# RL6955_IP_SVD register map
Vendor: Realtek
Registers are 32-bit, read-write, reset 0x0 unless marked. A register's access mark holds for its fields unless they carry their own. Offsets are from the block's base; [hi:lo] are bit positions; {n}, {i} and the like mark numbered series; <NAME> marks a mode.

## WMAC_PAGE7
Base 0x40000000
0x700 REG_MACID1
  [31:0] WMAC_MACID1_L — MAC Identification Number Register for port 1. relay mode as soft ap macid
0x704 REG_MACID1_1
  [15:0] WMAC_MACID1_H — MAC Identification Number Register for port 1. relay mode as soft ap macid
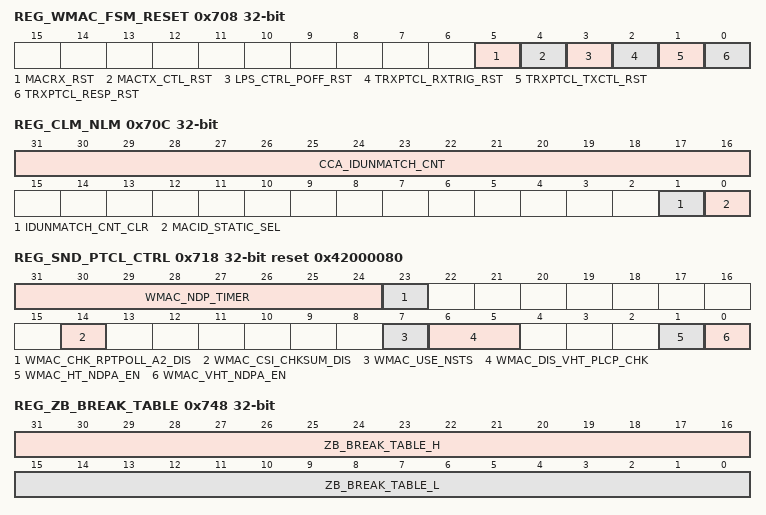
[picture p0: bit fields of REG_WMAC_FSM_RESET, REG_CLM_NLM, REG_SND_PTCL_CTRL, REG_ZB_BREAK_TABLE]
0x708 REG_WMAC_FSM_RESET wo
  [5] MACRX_RST — write 1 to RESET FSM of macrx
  [4] MACTX_CTL_RST — write 1 to RESET FSM of mactx_ctl
  [3] LPS_CTRL_POFF_RST — write 1 to RESET FSM of wmac_tlps_ctrl_poff
  [2] TRXPTCL_RXTRIG_RST — write 1 to RESET FSM of wmac_trxptcl_rxtig
  [1] TRXPTCL_TXCTL_RST — write 1 to RESET FSM of wmac_trxptcl_txctl
  [0] TRXPTCL_RESP_RST — write 1 to RESET FSM of wmac_trxptcl_resp
0x70C REG_CLM_NLM access per field
  [31:16] CCA_IDUNMATCH_CNT ro — not my packet counter
  [1] IDUNMATCH_CNT_CLR wo — write 1 to reset cca_idunmatch_cnt
  [0] MACID_STATIC_SEL rw — 1:statistic a1 match packet;0:statistic a1 match packet,my bss bc and mc packet
0x710 REG_MACID2
  [31:0] WMAC_MACID2_L — MAC Identification Number Register for port 2. relay mode, enable r_P2_WTNAP, as relay ap addr
0x714 REG_MACID2_1
  [15:0] WMAC_MACID2_H — MAC Identification Number Register for port 2 relay mode, enable r_P2_WTNAP, as relay ap addr
0x718 REG_SND_PTCL_CTRL reset 0x42000080
  [31:24] WMAC_NDP_TIMER — A timeout value for MAC to leave NDP_Rx_standby_state and go back to normal Rx mode. (unit: 2us)
  [23] WMAC_CHK_RPTPOLL_A2_DIS — 1: For any A1-matched BF Rpt Poll, send back VHT-CB 0: If A1-matched BF Rpt Poll's A2 fails to match the previous receiving NDPA's A2, do not send VHT-CB
  [14] WMAC_CSI_CHKSUM_DIS — 1:Disable check 16bit checksum value of csi report from BB 0:Enable check 16bit checksum value of csi report from BB
  [7] WMAC_USE_NSTS — 1: use Nsts as Nr, 0: use register value as Nr
  [6:5] WMAC_DIS_VHT_PLCP_CHK — [6]:1: disable check vhtsigb crc [5]:1: disable check vhtsiga crc
  [1] WMAC_HT_NDPA_EN — Set to 1, MAC would inform BB of preparing to receive NDP if the received NDP Announcement MPDU is valid.
  [0] WMAC_VHT_NDPA_EN — Set to 1, MAC would inform BB of preparing to receive NDP if the received NDPA is valid.
0x71C REG_BEAMFORM_STATUS
  [30] WMAC_CHECK_SOUNDING_SEQ — Set to 1,MAC would check sounding sequence number of received CSI report and transmitted NDPA
0x720 REG_ZB_STATISTIC_0 wo
  [0] STATIS_ZB_RSTB
0x724 REG_ZB_STATISTIC_1 ro
  [31:0] STATIS_ZG_L — for statistic
0x728 REG_ZB_STATISTIC_2 ro
  [31:0] STATIS_ZG_H — for statistic
0x740 REG_ZB_COEX_TABLE_1
  [31:0] ZB_COEX_TABLE_1 — coexistence table between WLAN and Zigbee, selected by BIT_COEX_TABLE_SEL = 0
0x744 REG_ZB_COEX_TABLE_2
  [31:0] ZB_COEX_TABLE_2 — coexistence table between WLAN and Zigbee, selected by BIT_COEX_TABLE_SEL = 1
0x748 REG_ZB_BREAK_TABLE
  [31:16] ZB_BREAK_TABLE_H — Table used to break ZB activity, when new WLAN request is coming and ZB is on transmitting or receiving
  [15:0] ZB_BREAK_TABLE_L — Table used to break WLAN activity, when new ZB request is coming and WLAN is on transmitting or receiving
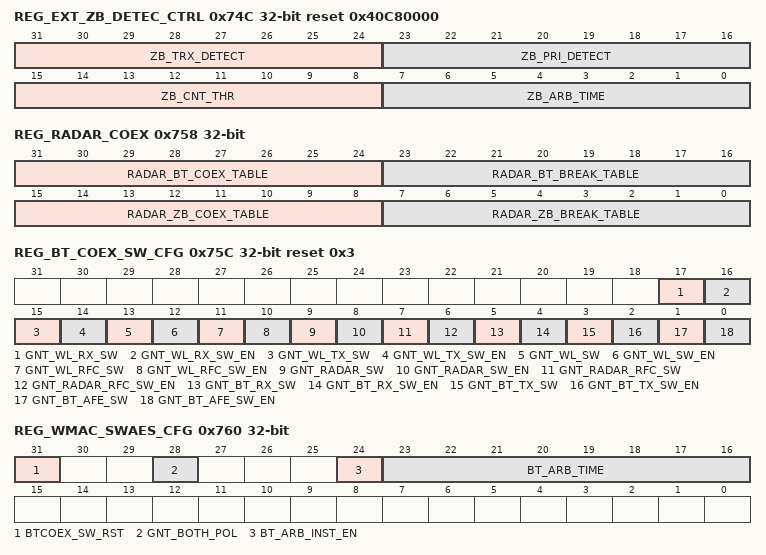
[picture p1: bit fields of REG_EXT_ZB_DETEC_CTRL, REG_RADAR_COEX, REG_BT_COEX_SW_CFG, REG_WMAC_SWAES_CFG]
0x74C REG_EXT_ZB_DETEC_CTRL reset 0x40C80000
  [31:24] ZB_TRX_DETECT — Valid if BIT_ZIGBEE_MODE = 1 & BIT_EXT_ZIGBEE_MODE = 0 (external mode, directional PRIORITY) After ZB_PRI_DETECT_TIME duration, if ZB_PRIORITY is low or goes low during ZB_TRX_INIT_DETECT_TIME, Zigbee will receive packets; otherwise, if ZG_PRIORITY is high or goes high, ZB will TX data. Unit 1us.
  [23:16] ZB_PRI_DETECT — Valid if BIT_ZIGBEE_MODE = 1 & BIT_EXT_ZIGBEE_MODE = 0 (external mode, directional PRIORITY) After ZB_REQUEST asserting, if ZG_PRIORITY is asserted within this ZB_PRI_DETECT_TIME duration, ZG will initiate high priority activities; otherwise, if ZB_PRIORITY is not asserted within this duration, it would be low priority activities. Units 1us. (0-255us)
  [15:8] ZB_CNT_THR — ZB count threshold, unit: us
  [7:0] ZB_ARB_TIME — 8 bit timer register : Arbitration window of ZB trx request (unit: us)
0x758 REG_RADAR_COEX
  [31:24] RADAR_BT_COEX_TABLE — COEX table of radar & BT, radar force wl_tx = 1, wl_pri = 1
  [23:16] RADAR_BT_BREAK_TABLE — BREAK table of radar & BT, radar force wl_tx = 1, wl_pri = 1
  [15:8] RADAR_ZB_COEX_TABLE — COEX table of radar & ZB, radar force wl_tx = 1, wl_pri = 1
  [7:0] RADAR_ZB_BREAK_TABLE — BREAK table of radar & ZB, radar force wl_tx = 1, wl_pri = 1
0x75C REG_BT_COEX_SW_CFG reset 0x3
  [17] GNT_WL_RX_SW — SW control GNT_WL_RX
  [16] GNT_WL_RX_SW_EN — SW control GNT_WL_RX enable
  [15] GNT_WL_TX_SW — SW control GNT_WL_TX
  [14] GNT_WL_TX_SW_EN — SW control GNT_WL_TX enable
  [13] GNT_WL_SW — SW control GNT_WL
  [12] GNT_WL_SW_EN — SW control GNT_WL enable
  [11] GNT_WL_RFC_SW — SW control GNT_WL_RFC
  [10] GNT_WL_RFC_SW_EN — SW control GNT_WL_RFC enable
  [9] GNT_RADAR_SW — SW control GNT_RADAR
  [8] GNT_RADAR_SW_EN — SW control GNT_RADAR enable
  [7] GNT_RADAR_RFC_SW — SW control GNT_RADAR_RFC
  [6] GNT_RADAR_RFC_SW_EN — SW control GNT_RADAR_RFC enable
  [5] GNT_BT_RX_SW — SW control GNT_BT_RX
  [4] GNT_BT_RX_SW_EN — SW control GNT_BT_RX enable
  [3] GNT_BT_TX_SW — SW control GNT_BT_TX
  [2] GNT_BT_TX_SW_EN — SW control GNT_BT_TX enable
  [1] GNT_BT_AFE_SW — SW control BT AFE
  [0] GNT_BT_AFE_SW_EN — SW control BT AFE enable
0x760 REG_WMAC_SWAES_CFG
  [31] BTCOEX_SW_RST
  [28] GNT_BOTH_POL — grant both choose GNT_BT polarity: 0 : deassert GNT_BT signal as PTA grant both WiFI and BT. 1 : assert GNT_BT signal as PTA grant both WiFi and BT.
  [24] BT_ARB_INST_EN — 1: enable GNT_BT_BYPASS_PRIORITY 0 : disable
  [23:16] BT_ARB_TIME — 8 bit timer register : Arbitration window of bt trx request ( in the unit of us)
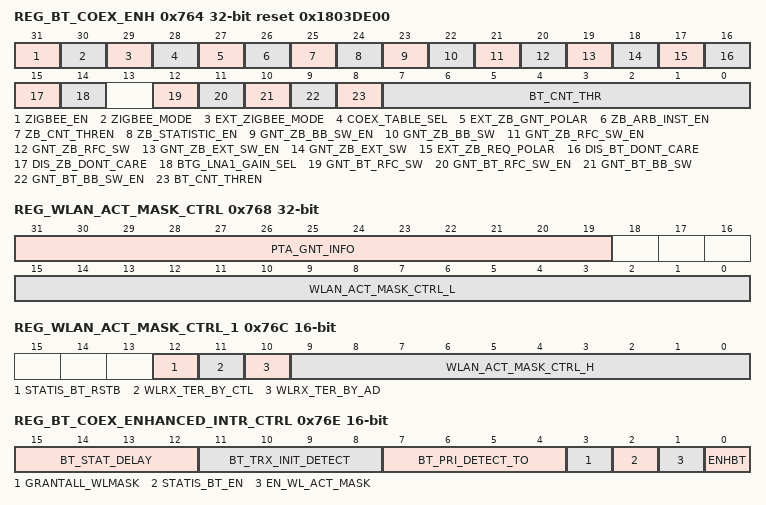
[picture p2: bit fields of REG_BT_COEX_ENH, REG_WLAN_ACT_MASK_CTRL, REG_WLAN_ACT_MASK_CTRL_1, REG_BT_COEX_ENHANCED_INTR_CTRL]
0x764 REG_BT_COEX_ENH reset 0x1803DE00
  [31] ZIGBEE_EN — Enable ZigBee function
  [30] ZIGBEE_MODE — 0: SOC 1: external
  [29] EXT_ZIGBEE_MODE — The mode of external ZigBee 1: static PRIORITY 0: directional PRIORITY
  [28] COEX_TABLE_SEL — Select coexistence table for WLAN & ZB 0: BIT_COEX_TABLE_WL_ZB_1 1: BIT_COEX_TABLE_WL_ZB_2
  [27] EXT_ZB_GNT_POLAR — Select the polar of ZB_GRANT, for extarnal ZB 0: low active 1: high active
  [26] ZB_ARB_INST_EN — 1: enable the time limit of ZigBee request (zb_pri | zb_rx | zb_tx), PTA is valid during ( <=BIT_ZB_ARB_TIME) 0: disable Co-work with BIT_ZB_ARB_TIME
  [25] ZB_CNT_THREN — ZB count threshold enable, for statistics co-work with BIT_ZB_CNT_THR
  [24] ZB_STATISTIC_EN — enable statistic of ZB
  [23] GNT_ZB_BB_SW_EN — Enable SW control gnt_zb_bb
  [22] GNT_ZB_BB_SW — SW value
  [21] GNT_ZB_RFC_SW_EN — Enable SW control gnt_zb_rfc
  [20] GNT_ZB_RFC_SW — SW value
  [19] GNT_ZB_EXT_SW_EN — Enable SW control gnt_zb_o of external ZigBee
  [18] GNT_ZB_EXT_SW — SW value, external ZigBee
  [17] EXT_ZB_REQ_POLAR — Select the polar of ZB_REQUEST, for static mode external ZB 0: low active 1: high active
  [16] DIS_BT_DONT_CARE
  [15] DIS_ZB_DONT_CARE
  [14] BTG_LNA1_GAIN_SEL
  [12] GNT_BT_RFC_SW — SW control BT RF
  [11] GNT_BT_RFC_SW_EN — SW control BT RF enable
  [10] GNT_BT_BB_SW — SW control BT baseband
  [9] GNT_BT_BB_SW_EN — SW control BT baseband enable
  [8] BT_CNT_THREN — BT count threshold enable
  [7:0] BT_CNT_THR — BT count threshold
0x768 REG_WLAN_ACT_MASK_CTRL access per field
  [31:19] PTA_GNT_INFO ro — [0]: gnt_wl [1]: gnt_bt_bb [2]: gnt_bt_rfc [3]: gnt_zb_bb [4]: gnt_zb_rfc [5]: gnt_wl_tx [6]: gnt_wl_rx [7]: gnt_bt_tx [8]: gnt_bt_rx [9]: gnt_bt_afe [10]: gnt_wl_rfc [11]: gnt_radar [12]: gnt_radar_rfc
  [15:0] WLAN_ACT_MASK_CTRL_L rw — [15:8]: WLAN will reserve channel for BT during MASK OFF duration. Unit 0.625ms [7:0]: WLAN can block BT during MASK On duration. Unit 0.625ms
0x76C REG_WLAN_ACT_MASK_CTRL_1 16-bit access per field
  [12] STATIS_BT_RSTB wo
  [11] WLRX_TER_BY_CTL rw — When wlan receive a control packet without fit address, whether the signal indicating wlan rx can be terminated as soon as the address check finish is not only controlled by r_WLRX_TER_BY_AD, but also should be refereed to this bit. 1: enable; 0: disable
  [10] WLRX_TER_BY_AD rw — When wlan receive the packet without fit address, the signal indicating wlan rx can be terminated as soon as the address check finish. This feature can be enabled by this bit. 1: en
  [9:0] WLAN_ACT_MASK_CTRL_H rw — [9]: Antenna diversity for 2 antenna mode: MAC_ANT_SEL = GNT_BT ^ ANT_DIVERDITY_SEL [8]: Enable the control of antenna selection through GNT_BT:GNT_BT=1: ANT_SEL for BT device; GNT_BT=0: ANT_SEL for WL device. [7:3]:RSVD [2]:When WLACT_LOW_GNTWL_EN = 1, the TRX of WLAN are blocked according to the BTCOEX table arbitration during MASK OFF duration. WLACT_LOW_GNTWL_EN = 0, the TRX of WLAN are paused during MASK OFF duration.. [1]:When WLACT_HIGH_GNTBT_EN = 1, the TRX of WLAN are blocked according to the BTCOEX table arbitration during MASK ON duration. When WLACT_HIGH_ GNTBT_EN = 0, the TRX of WLAN are not paused during MASK OFF duration. [0]:When NAV update is beyond this value, then NAV update is aborted. When this field is 0x00, NAV_UPPER function is disable. The unit is 128us.
0x76E REG_BT_COEX_ENHANCED_INTR_CTRL 16-bit
  [15:12] BT_STAT_DELAY — For CSR, BT_PRI and BT_STAT go high form low at the same time. Thus, BT_STAT need delay BT_STAT_DELAY time to trigger hardware. Unit: 1us
  [11:8] BT_TRX_INIT_DETECT — After BT_PRI asserting for BT_TRX_INIT_DETECT us, if BT_STAT is low, then BT will receive packets; otherwise, if BT goes high, BT will TX data. Unit 4us.
  [7:4] BT_PRI_DETECT_TO — After BT_PRI asserting, if BT_STAT is asserted within this TO duration, BT will initiate high priority activities; otherwise, if BT_STAT is not asserted within this duration, it would be low priority activities. Units 1us.
  [3] GRANTALL_WLMASK — grant all mask
  [2] STATIS_BT_EN — When this bit is set, the BT_ACT_STATISTICS counters starts counting
  [1] EN_WL_ACT_MASK — Enable WLAN_ACT Mask Function (related to 0x768h-0x76Dh)
  [0] ENHBT — Enable Enhanced BT Interface (we suggest to use with BT mode 2)
0x770 REG_BT_ENHANCED_CTRL0 ro
  [31:0] STATIS_BT0
0x774 REG_BT_ENHANCED_CTRL1 ro
  [31:0] STATIS_BT1
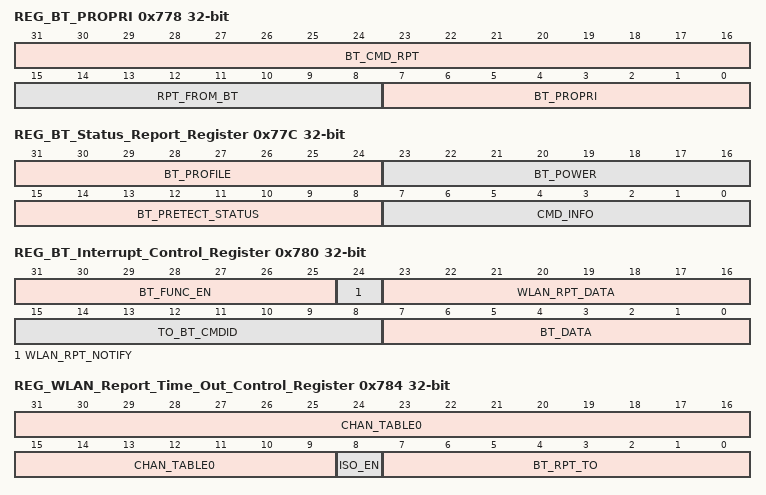
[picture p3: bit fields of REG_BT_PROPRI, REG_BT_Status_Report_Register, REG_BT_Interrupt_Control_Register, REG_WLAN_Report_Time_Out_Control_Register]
0x778 REG_BT_PROPRI access per field
  [31:16] BT_CMD_RPT ro
  [15:8] RPT_FROM_BT ro
  [7:0] BT_PROPRI rw — [7:6]: When EN_BT_PROFILE_OR_HID is set "1", hardware also need to checkthis value to trigger an interrupt. 0: default, TX and RX; 1: TX; 2: RX; 3: Reserved [5]: When the control of TDMA mode is firmware and firmware also receive signal that NULL packet for BT had sent, firmware can fill this bit to notify HW PTA to pull WLAN_ACT to low and the interval is Tbt [4]: 0: default, PTA TDMA mode is hardware mode. 1: enable firmware mode. [3]:0: default, disable PTA TDMA mode; 1: enable TDMA mode: a. WLAN_ACT default is high. b. Hardware mode: When NULL packet for BT had sent, hardware will notify PTA to start TDMA mode. Firmware mode: When NULL packet for BT had sent, hardware will trigger an interrupt to notify firmware. Then, firmware need to set TDMA_BT_START_NOTIFY to notify PTA to start TDMA mode [2]: 0: default, no matter which WLAN_ACT is high or low, PTA doesn't execute co-exist table scheme; 1: enable, When WLAN_ACT is high, PTA execute xo-exist table scheme [1]: Enable GPIO2 and GPIO3 exchange. (Note: need to enable mode2 and enhance 3 wire) If Enable RTK BT mode, set this bit to 1 to disable granting to BT device when arbitration [0]: Enable RTK BT mode
0x77C REG_BT_Status_Report_Register ro
  [31:24] BT_PROFILE — When WLAN received CMD_ID 0x3, it will recorder to this.
  [23:16] BT_POWER — When WLAN received CMD_ID 0x2, it will recorder to this
  [15:8] BT_PRETECT_STATUS — When WLAN received CMD_ID 0x0, it will recorder to this
  [7:0] CMD_INFO — command information from BT
0x780 REG_BT_Interrupt_Control_Register access per field
  [31:25] BT_FUNC_EN rw — [31]: When firmware had prepared packet to send to BT, it need to set this bit to notify hardware that it can transmit. 0: There isn't a valid packet in register" WLAN_RPT_ PKT". 1: There is a valid packet in register" WLAN_RPT_ PKT". [30]: Enable two interrupt:1) PTA sent the report packet successfully; 2) PTA sent a query packet 0: Disable 1: Enable [29]: When MAC had sent NULL packet for BT and firmware also set nav_for_bt bit, hardware triggers an interrupt to notify firmware. 0: Disable 1: Enable [28]: When WLAN receive cmd_id "0", hardware trigger an interrupt to notify firmware. 0: Disable 1: Enable [27]: When WLAN received the packet including BT Power and check register "BT_STATUS_RPT", if data contents aren't the same, hardware can trigger an interrupt to notify firmware. 0: Disable 1: Enable [26]: When WLAN received the packet including BT channel number, hardware can trigger an interrupt to notify firmware. 0: Disable 1: Enable [25]: When WLAN received the packet including that BT had multi-slots, hardware can trigger an interrupt to notify firmware. 0: Disable 1: Enable
  [24] WLAN_RPT_NOTIFY rw — [24]:Enable two interrupt 1) When WLAN received the packet including that WLAN specific profile and check register "BT_STATUS_RPT", if data contents aren't the same, hardware can trigger an interrupt to notify firmware. 2) When WLAN received the report packet including HID information, hardware will trigger an interrupt to notify firmware. 0: Disable 1: Enable
  [23:16] WLAN_RPT_DATA rw — Data contents, When the report packet had sent, hardware will clear this register.
  [15:8] TO_BT_CMDID rw — Command id: 0x80~FF
  [7:0] BT_DATA ro — When WLAN received the packet BT sent, hardware will place data to this register in addition to CMD_ID 0x0 ~ 0x3.
0x784 REG_WLAN_Report_Time_Out_Control_Register
  [31:9] CHAN_TABLE0 — 0: leave PTA 1: enter PTA
  [8] ISO_EN — Isolation table enable bit. 0: disable 1: enable
  [7:0] BT_RPT_TO — When WLANＨW received query packet, HW timer counts. If timer equals to WLAN_RPT_TO and HW can"t send packet, it will give up query packet at this time. When BT sent another query packet, WLAN HW need to send the previous packet and it shouldn't trigger an interrupt to firmware. Unit: 4us.
0x788 REG_BT_Isolation_Table_Register_Register_1
  [31:0] CHAN_TABLE1 — 0: leave PTA 1: enter PTA
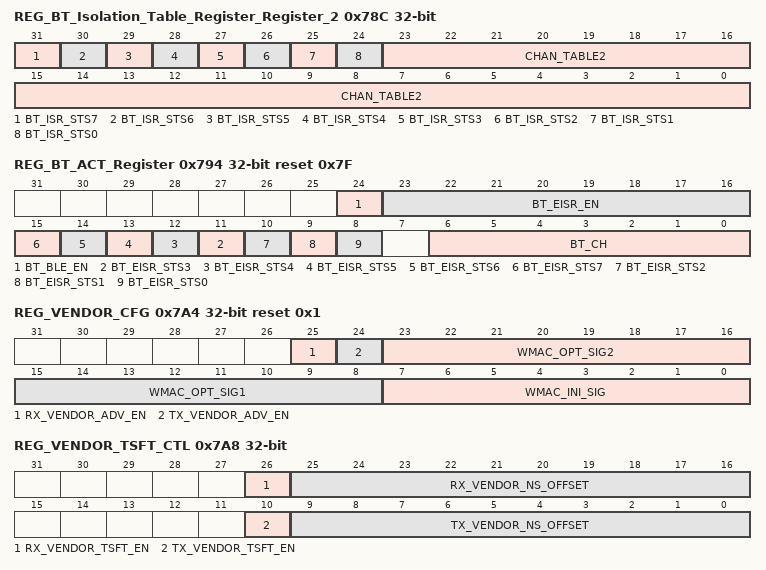
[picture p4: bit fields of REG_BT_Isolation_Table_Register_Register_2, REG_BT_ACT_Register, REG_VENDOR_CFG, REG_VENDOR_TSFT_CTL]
0x78C REG_BT_Isolation_Table_Register_Register_2 access per field
  [31] BT_ISR_STS7 ro — When WLAN received the report packet including HID information, hardware will trigger an interrupt to notify firmware
  [30] BT_ISR_STS6 ro — When WLAN received a query packet, hardware triggers an interrupt to notify firmware
  [29] BT_ISR_STS5 ro — When MAC had sent NULL packet for BT and firmware also set nav_for_bt bit, hardware triggers an interrupt to notify firmware
  [28] BT_ISR_STS4 ro — When PTA sent the report packet successfully, hardware triggers an interrupt to notify firmware.
  [27] BT_ISR_STS3 ro — When WLAN received the packet including BT Power and check register "BT_STATUS_RPT", if data contents aren't the same, hardware can trigger an interrupt to notify firmware
  [26] BT_ISR_STS2 ro — When WLAN received the packet including BT channel number, hardware can trigger an interrupt to notify firmware.
  [25] BT_ISR_STS1 ro — When WLAN received the packet including that BT had multi-slots, hardware can trigger an interrupt to notify firmware
  [24] BT_ISR_STS0 ro — When WLAN received the packet including that WLAN specific profile and check register "BT_STATUS_RPT", if data contents aren't the same, hardware can trigger an interrupt to notify firmware.
  [23:0] CHAN_TABLE2 rw — 0: leave PTA 1: enter PTA
0x790 REG_BT_TDMA_Time_Register
  [31:0] BT_TIME — [31:6]: The time is that WLAN_ACT is low. Unit: us [5:0]: When wifi detected the raising edge of BT report packet, wifi need to counter BT_RPT_SAMPLE_RATE. Then hw could detect which is high or low. Uint: 20 ns
0x794 REG_BT_ACT_Register access per field reset 0x7F
  [24] BT_BLE_EN rw — Decide the GNT_BT_TX / RX 0: GNT_BT_TX = GNT_BT & BT_TX ; GNT_BT_RX = GNT_BT & BT_RX 1: GNT_BT_TX = GNT_BT & (BT_TX | BT_BLE) ; GNT_BT_RX = GNT_BT & (BT_RX | BT_BLE)
  [23:16] BT_EISR_EN rw — BT eisr enable
  [n+8] BT_EISR_STS{n} ro (n=3..7)
  [10] BT_EISR_STS2 ro — [10]: When BT_ACT signal is falling edge, it will trigger an interrupt.
  [9] BT_EISR_STS1 ro — [9]: When BT_ACT signal is raising edge, it will trigger an interrupt
  [8] BT_EISR_STS0 ro — [8]: When BT_TIME expired, it will trigger an interrupt.
  [6:0] BT_CH ro — When hardware receive cm_id "1", it will recorder to this.
0x7A4 REG_VENDOR_CFG reset 0x1
  [25] RX_VENDOR_ADV_EN, [24] TX_VENDOR_ADV_EN, [23:16] WMAC_OPT_SIG2, [15:8] WMAC_OPT_SIG1, [7:0] WMAC_INI_SIG
0x7A8 REG_VENDOR_TSFT_CTL
  [26] RX_VENDOR_TSFT_EN — vendor tsft emable for rx
  [25:16] RX_VENDOR_NS_OFFSET — vendor ns offset for rx
  [10] TX_VENDOR_TSFT_EN — vendor tsft emable for tx
  [9:0] TX_VENDOR_NS_OFFSET — vendor ns offset for tx
0x7B0 REG_TCR_TSFT_OFS
  [29:0] WMAC_TCR_TSFT_NS_OFS — tcr_tsft_ns_ofs
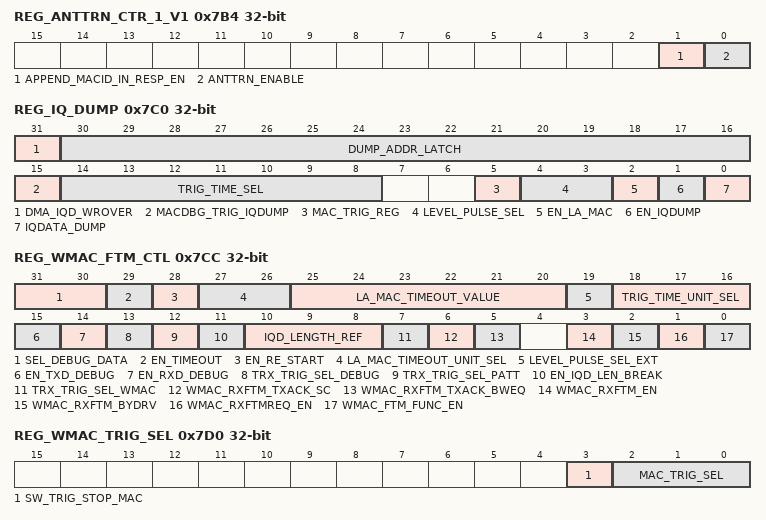
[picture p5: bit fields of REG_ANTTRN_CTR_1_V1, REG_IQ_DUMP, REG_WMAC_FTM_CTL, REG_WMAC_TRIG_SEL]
0x7B4 REG_ANTTRN_CTR_1_V1
  [1] APPEND_MACID_IN_RESP_EN — Whether to append MACID in the rx descriptor of rx response packet
  [0] ANTTRN_ENABLE — Enable the antenna training function
0x7C0 REG_IQ_DUMP access per field
  [31] DMA_IQD_WROVER ro
  [30:16] DUMP_ADDR_LATCH ro
  [15] MACDBG_TRIG_IQDUMP rw — Enable dump bb ADC signal trigger from MAC debug port which controled by r_LEVEL_PULSE_SEL.
  [14:8] TRIG_TIME_SEL rw — dump ok time to finish dump signal(unit is 1us)
  [5] MAC_TRIG_REG rw — dump bb ADC sel mac strigger even write this reg to 1 to trig dump finish
  [4:3] LEVEL_PULSE_SEL rw — if dump bb ADC signal : [3] for sel mac trigger event if dump mac dbg signal [4:3] : 2'b00 : level signal match [4:3] : 2'b01 : posedge match [4:3] : 2'b10 : negdge match
  [2] EN_LA_MAC rw — enable dump mac dbg signal
  [1] EN_IQDUMP rw — enable dump bb ADC signal
  [0] IQDATA_DUMP rw — enable data dump for txpktbuffer high 64K
0x7C4 REG_MASK_LA_MAC
  [31:0] WMAC_MASK_LA_MAC
0x7C8 REG_MATCH_REF_MAC
  [31:0] WMAC_MATCH_REF_MAC
0x7CC REG_WMAC_FTM_CTL
  [31:30] SEL_DEBUG_DATA
  [29] EN_TIMEOUT — Set this bit to 1 to reset mdpk read pointer
  [28] EN_RE_START — Before setting 0x7C0[1:0] =2'b11, set this bit to 1 to enable MDPK access mode
  [27:26] LA_MAC_TIMEOUT_UNIT_SEL — LA mode triggered by mac debug port timeout value unit selection. 2'b00: 1us, 2'b01:32us, 2'b10: 1ms, 2'b11:RSVD
  [25:20] LA_MAC_TIMEOUT_VALUE — LA mode triggered by mac debug port timeout value, available with non-zero value.
  [19] LEVEL_PULSE_SEL_EXT — LA mode triggered by mac debug port timeout event
  [18:16] TRIG_TIME_UNIT_SEL — Select trigger time unit of 0x7C0[14:8]. 3'b000 : 1us , 3'b001 : 2us , 3'b010 : 4us , 3'b011 : 8us , 3'b100 : 16us , 3'b101 : 32us , 3'b110 : 64us, 3'b111 : RSV
  [15] EN_TXD_DEBUG
  [14] EN_RXD_DEBUG
  [13] TRX_TRIG_SEL_DEBUG
  [12] TRX_TRIG_SEL_PATT
  [11] EN_IQD_LEN_BREAK
  [10:8] IQD_LENGTH_REF
  [7] TRX_TRIG_SEL_WMAC
  [6] WMAC_RXFTM_TXACK_SC — When HW receive FTM pkt, HW will use RX FTM BW as response ACK TXBW.
  [5] WMAC_RXFTM_TXACK_BWEQ — When HW receive FTM pkt, HW will use RX FTM SC as response ACK TXSC.
  [3] WMAC_RXFTM_EN — If BIT_FTM_TYPE = 1 && BIT_RXFTM_EN=1, HW will parsing rx packet, to find FTM request frame.
  [2] WMAC_RXFTM_BYDRV — If set this bit to 1,Rx FTMREQ/FTM can be receive into rxpktbuffer.
  [1] WMAC_RXFTMREQ_EN — If BIT_FTM_TYPE = 1 && BIT_RXFTMREQ_EN=1, HW will parsing rx packet, to find FTM request frame.
  [0] WMAC_FTM_FUNC_EN — Fine timing measurement function; 0: Disable 1:enable
0x7D0 REG_WMAC_TRIG_SEL
  [3] SW_TRIG_STOP_MAC — during TXD_DEBUG or RXD_DEBUG mode, set CR 0->1 will trig iqdump stop
  [2:0] MAC_TRIG_SEL — dump bb ADC sel mac strigger even 2'b00 : rxpkt ok trig dump ok 2'b01 : rxpkt_fauil trig dump ok 2'b10 : rxpkt cca rise edge to trig dump ok 2'b11: rx type match
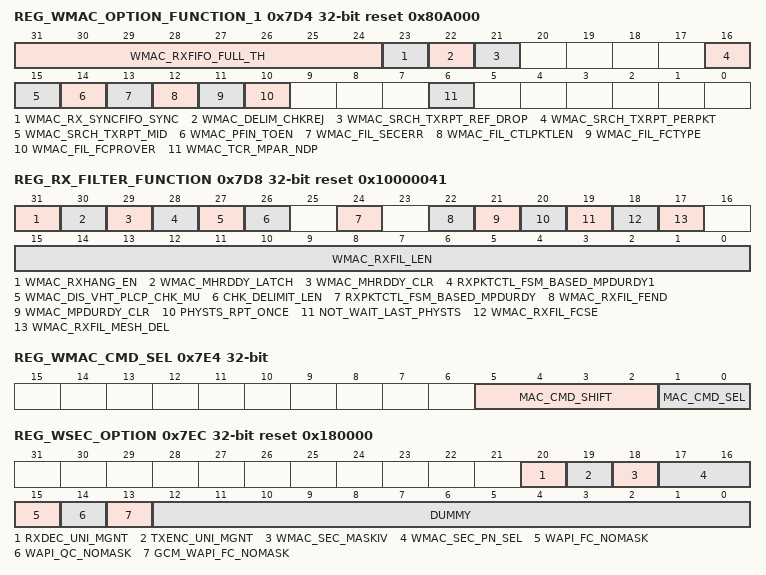
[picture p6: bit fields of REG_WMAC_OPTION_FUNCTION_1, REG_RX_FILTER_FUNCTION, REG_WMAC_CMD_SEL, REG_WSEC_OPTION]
0x7D4 REG_WMAC_OPTION_FUNCTION_1 reset 0x80A000
  [31:24] WMAC_RXFIFO_FULL_TH — csi buffer full window size
  [23] WMAC_RX_SYNCFIFO_SYNC
  [22] WMAC_DELIM_CHKREJ — 1:state is delim check rx error to jump to error state 0:state is delim check rx_error_to_end to jump to error state
  [21] WMAC_SRCH_TXRPT_REF_DROP — when this bit is set 1, reference macid drop information when macid search
  [16] WMAC_SRCH_TXRPT_PERPKT — enable search txrpt buffer for macid every pkt
  [15] WMAC_SRCH_TXRPT_MID — enable search txrpt buffer for macid
  [14] WMAC_PFIN_TOEN — rx fifo fsm flush state timeout to error stage
  [13] WMAC_FIL_SECERR — sec len error drop(sec len is zero)
  [12] WMAC_FIL_CTLPKTLEN — drop the rx pkt if the rx ctrl pkt len large than r_WMAC_RX_FIL_LEN
  [11] WMAC_FIL_FCTYPE — drop the ofdm pkt if the rx ofdm leg pkt fc type is 2'b11
  [10] WMAC_FIL_FCPROVER — drop the ofdm pkt if the rx ofdm leg pkt fc version illegal
  [6] WMAC_TCR_MPAR_NDP — nop ok check bb ndp vld & mac rx ndp check ok
0x7D8 REG_RX_FILTER_FUNCTION reset 0x10000041
  [31] WMAC_RXHANG_EN — Force read error content from fifo to solve rxhang.
  [30] WMAC_MHRDDY_LATCH — enable mac header ready latch when state is not wait fcs or error
  [29] WMAC_MHRDDY_CLR — enable mac header start to clear mac header ready latch signal
  [28] RXPKTCTL_FSM_BASED_MPDURDY1 — Adjust mpdu_rdy timing to solve FSM behavier error.
  [27] WMAC_DIS_VHT_PLCP_CHK_MU — Disable check sigb crc value of MU plcp header.
  [26] CHK_DELIMIT_LEN — Drop mpdu if delimeter mpdu length smaller than mac header length + 4.
  [24] RXPKTCTL_FSM_BASED_MPDURDY — when this bit is set 1, rxpktfifo_ctl FSM jumps based on mpdu_valid(all MPDU data has been transferred to rxpktbuffer), when this bit is set 0, rxpktfifo_ctl FSM jumps based on fcs_valid(all MPDU data has been parsed by rx_parser)
  [22] WMAC_RXFIL_FEND — when this bit set 1,icvmic_valid signal is cleared when icvmic_rdy is valid(ICV/MIC is parsed)
  [21] WMAC_MPDURDY_CLR — when the bit is set 1, the last MPDU which will be transferred to rxpktfifo is ready and error occurs, mpdu_rdy signal is also valid(is means all MPDU data has been transferred to rxpktbuffer)
  [20] PHYSTS_RPT_ONCE — keep original physts rx design, only use the last physts (rx after data_on fall).
  [19] NOT_WAIT_LAST_PHYSTS — last mpdu don't wait last physts, use the current physts in physts buffer
  [18] WMAC_RXFIL_FCSE — If rx pkt is not ampdu and rejected, reset rxpkt_ctl FSM immediately after parsing header
  [17] WMAC_RXFIL_MESH_DEL — drop the ofdm pkt if the rx ofdm leg pkt fc type is 2'b11
  [15:0] WMAC_RXFIL_LEN — use with 0x7D4[12]
0x7E0 REG_WMAC_OPTION_FUNCTION_3 reset 0x1845A5
  [20:0] WMAC_TXNDP_SIGB — SIGB for NDP packet when BW =40MHz
0x7E4 REG_WMAC_CMD_SEL
  [5:2] MAC_CMD_SHIFT, [1:0] MAC_CMD_SEL
0x7E8 REG_WMAC_DBG_SHIFT ro
  [31:0] MACTX_CMD_SHIFT
0x7EC REG_WSEC_OPTION reset 0x180000
  [20] RXDEC_UNI_MGNT — decryption enable of rx unicast management pkt, 0x680[3] shall also be set valid
  [19] TXENC_UNI_MGNT — encryption enable of tx unicast management pkt, 0x680[2] shall also be set valid
  [18] WMAC_SEC_MASKIV — MASK IV[15:8] for GCMP security
  [17:16] WMAC_SEC_PN_SEL — Security GCMP header PN selection
  [15] WAPI_FC_NOMASK
  [14] WAPI_QC_NOMASK
  [13] GCM_WAPI_FC_NOMASK
  [12:0] DUMMY
